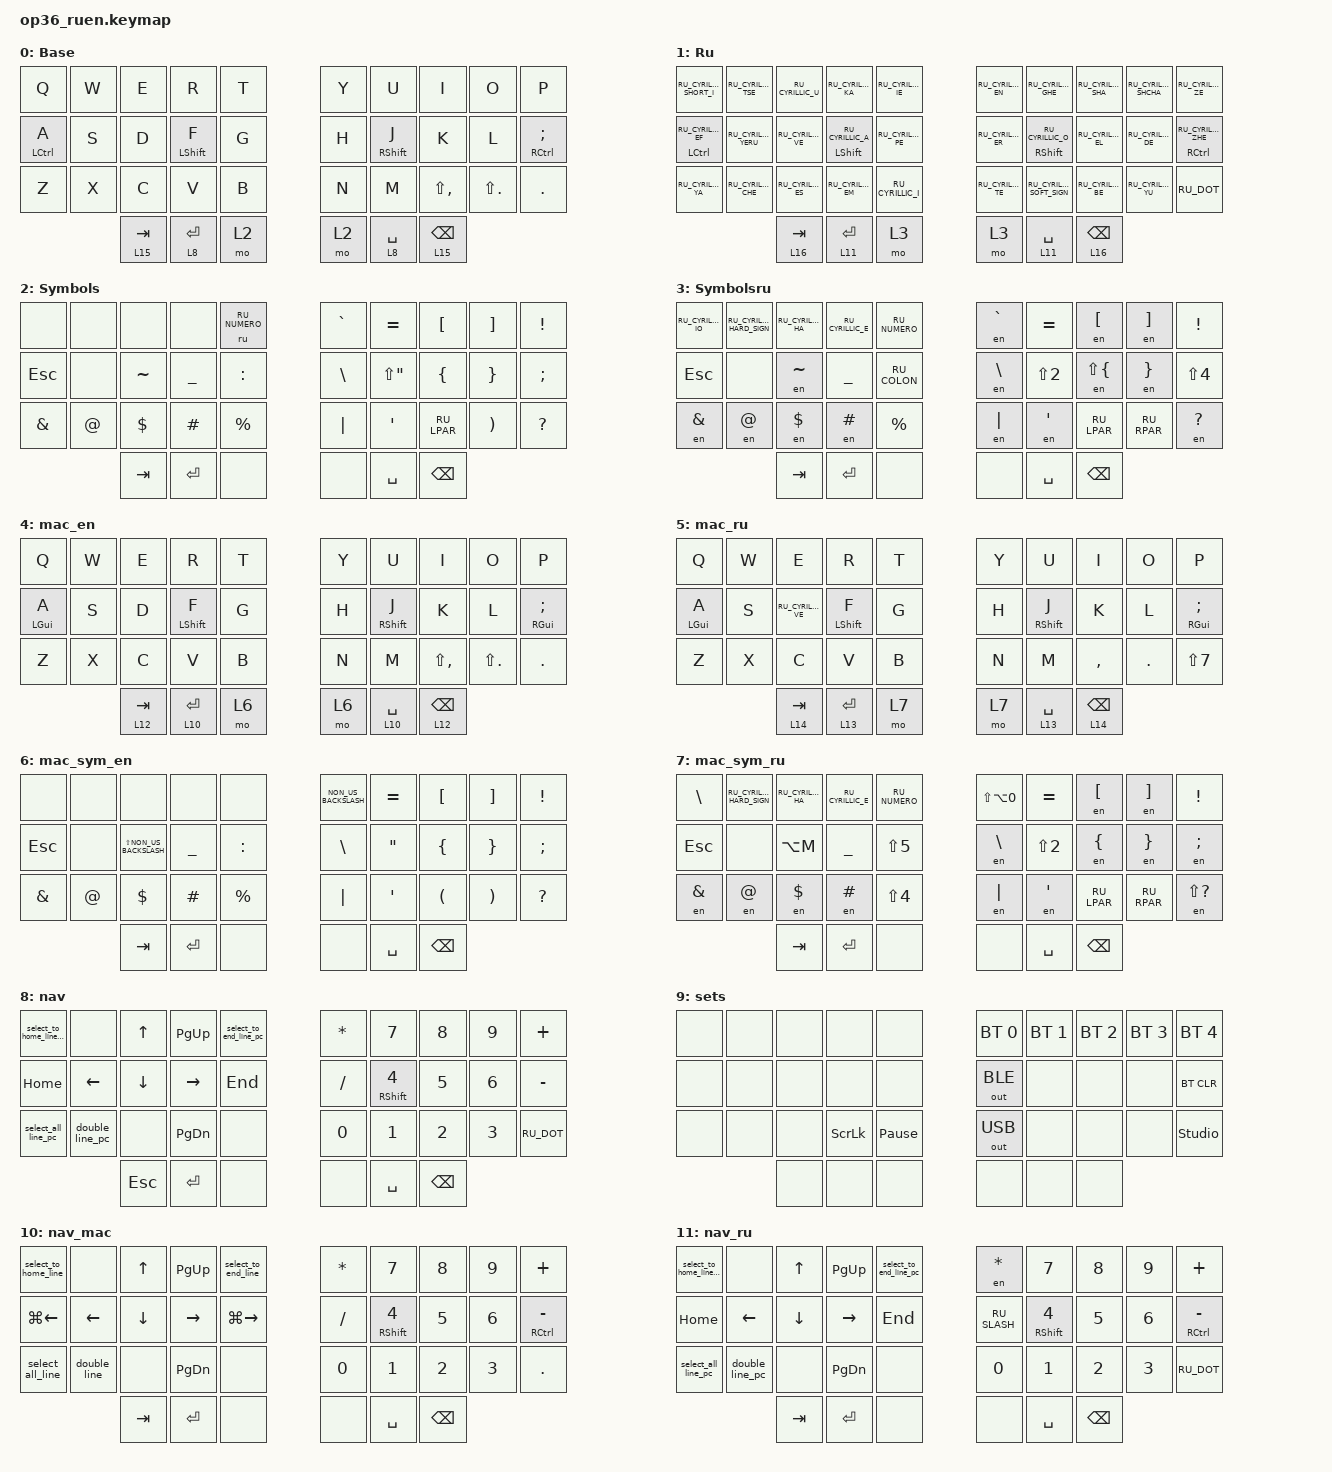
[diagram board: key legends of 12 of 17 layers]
#include "keys_ru.h"
#include "keys_ru.h"
#include <behaviors.dtsi>
#include <dt-bindings/zmk/bt.h>
#include <dt-bindings/zmk/keys.h>
#include <dt-bindings/zmk/outputs.h>

&mt {
    quick-tap-ms = <200>;
    flavor = "tap-preferred";
    require-prior-idle-ms = <125>;
};

/ {
    behaviors {
        hml: home_row_mod_left {
            compatible = "zmk,behavior-hold-tap";
            #binding-cells = <2>;
            flavor = "balanced";
            require-prior-idle-ms = <100>;
            tapping-term-ms = <160>;
            quick-tap-ms = <120>;
            bindings = <&kp>, <&kp>;

            hold-trigger-key-positions = <5 6 7 8 9 15 16 17 18 19 25 26 27 28 29 33 34 35>;
            hold-trigger-on-release;
        };

        hmr: home_row_mod_right {
            compatible = "zmk,behavior-hold-tap";
            #binding-cells = <2>;
            flavor = "balanced";
            require-prior-idle-ms = <100>;
            tapping-term-ms = <160>;
            quick-tap-ms = <120>;
            bindings = <&kp>, <&kp>;

            hold-trigger-key-positions = <0 1 2 3 4 10 11 12 13 14 20 21 22 23 24 30 31 32>;
            hold-trigger-on-release;
        };
    };

    combos {
        compatible = "zmk,combos";

        cmben {
            bindings = <&layer_en>;
            key-positions = <12 13>;
            layers = <1>;
        };

        cmbru {
            bindings = <&layer_ru>;
            key-positions = <12 13>;
            layers = <0>;
        };

        to_mac {
            bindings = <&mac_layer_en>;
            key-positions = <31 34>;
            layers = <0 1>;
        };

        to_base {
            bindings = <&layer_en>;
            key-positions = <30 35>;
            layers = <4 5>;
        };

        cmd_mac_ru {
            bindings = <&mac_layer_ru>;
            key-positions = <12 13>;
            layers = <4>;
        };

        cmd_mac_en {
            bindings = <&mac_layer_en>;
            key-positions = <12 13>;
            layers = <5>;
        };

        colon_en {
            bindings = <&kp COLON>;
            key-positions = <16 17>;
            layers = <0 2 4 6>;
        };

        colon_ru {
            bindings = <&kp RU_COLON>;
            key-positions = <16 17>;
            layers = <1 3>;
        };

        comma_en {
            bindings = <&kp COMMA>;
            key-positions = <26 27>;
            layers = <0 2 4 6 8>;
        };

        comma_ru {
            bindings = <&kp LS(SLASH)>;
            key-positions = <26 27>;
            layers = <1 3 11>;
        };

        to_layer_en {
            bindings = <&to 0>;
            key-positions = <0 3>;
            layers = <1>;
        };

        to_layer_mac_en {
            bindings = <&to 4>;
            key-positions = <0 3>;
            layers = <5>;
        };

        comma_mac_ru {
            bindings = <&kp LS(NUMBER_6)>;
            key-positions = <26 27>;
            layers = <5 7>;
        };

        colon_mac_ru {
            bindings = <&kp LS(NUMBER_5)>;
            key-positions = <16 17>;
            layers = <5 7>;
        };

        layer_en {
            bindings = <&kp NUMBER_0>;
            key-positions = <32 33>;
            layers = <0>;
        };

        layer_ru {
            bindings = <&kp NUMBER_1>;
            key-positions = <32 33>;
            layers = <1>;
        };

        layer_mac {
            bindings = <&kp NUMBER_4>;
            key-positions = <32 33>;
            layers = <4>;
        };

        layer_mac_ru {
            bindings = <&kp NUMBER_5>;
            key-positions = <32 33>;
            layers = <5>;
        };

        alt_l {
            bindings = <&kp LEFT_ALT>;
            key-positions = <11 12>;
        };

        alt_r {
            bindings = <&kp RIGHT_ALT>;
            key-positions = <17 18>;
        };

        dont_tap_to_mac {
            bindings = <&none>;
            key-positions = <31 34>;
            layers = <4 5>;
        };

        dont_tap_to_base {
            bindings = <&none>;
            key-positions = <30 35>;
            layers = <0 1>;
        };

        mac_ctrl_left {
            bindings = <&kp LCTRL>;
            key-positions = <21 22>;
            layers = <4 5 6 7 10 13 12>;
        };

        mac_ctrl_right {
            bindings = <&kp RCTRL>;
            key-positions = <27 28>;
            layers = <4 5 6 7 10 13 12>;
        };

        layer_sets {
            bindings = <&mo 9>;
            key-positions = <2 3>;
        };

        pc_gui_left {
            bindings = <&kp LEFT_GUI>;
            key-positions = <22 21>;
            layers = <0 1 2 3 8 9 11 15 16>;
        };

        pc_gui_right {
            bindings = <&kp LEFT_GUI>;
            key-positions = <27 28>;
            layers = <0 1 2 3 8 9 11 15 16>;
        };
    };

    macros {
        to_ru: to_ru {
            compatible = "zmk,behavior-macro";
            #binding-cells = <0>;
            bindings = <&kp LC(LS(NUMBER_2))>;
            label = "TO_RU";
            wait-ms = <0>;
            tap-ms = <30>;
        };

        to_en: to_en {
            compatible = "zmk,behavior-macro";
            #binding-cells = <0>;
            bindings = <&kp LS(LC(NUMBER_1))>;
            label = "TO_EN";
            wait-ms = <0>;
            tap-ms = <30>;
        };

        layer_en: layer_en {
            compatible = "zmk,behavior-macro";
            #binding-cells = <0>;
            bindings = <&to 0 &to_en>;
            label = "LAYER_EN";
            wait-ms = <0>;
            tap-ms = <30>;
        };

        layer_ru: layer_ru {
            compatible = "zmk,behavior-macro";
            #binding-cells = <0>;
            bindings = <&to 1 &to_ru>;
            label = "LAYER_RU";
            tap-ms = <30>;
            wait-ms = <0>;
        };

        en: en {
            compatible = "zmk,behavior-macro-one-param";
            #binding-cells = <1>;
            bindings =
                <&to_en>,
                <&macro_wait_time 50>,
                <&macro_press>,
                <&macro_param_1to1 &kp MACRO_PLACEHOLDER>,
                <&macro_pause_for_release>,
                <&macro_release>,
                <&macro_param_1to1 &kp MACRO_PLACEHOLDER>,
                <&macro_tap>,
                <&macro_wait_time 50>,
                <&to_ru>;

            label = "EN";
            wait-ms = <30>;
            tap-ms = <30>;
        };

        mac_layer_ru: mac_layer_ru {
            compatible = "zmk,behavior-macro";
            #binding-cells = <0>;
            bindings = <&to 5 &to_ru>;
            label = "MAC_LAYER_RU";
        };

        mac_layer_en: mac_layer_en {
            compatible = "zmk,behavior-macro";
            #binding-cells = <0>;
            bindings = <&to 4 &to_en>;
            label = "MAC_LAYER_EN";
        };

        select_all_line: to_all_line {
            compatible = "zmk,behavior-macro";
            #binding-cells = <0>;
            bindings =
                <&kp LG(LEFT)>,
                <&macro_wait_time 30>,
                <&kp LS(LG(RIGHT))>;

            label = "TO_ALL_LINE";
        };

        code_block: code_block {
            compatible = "zmk,behavior-macro";
            #binding-cells = <0>;
            bindings =
                <&kp GRAVE &kp GRAVE &kp GRAVE &kp R &kp U &kp S &kp T>,
                <&macro_wait_time 50>,
                <&kp ENTER>,
                <&macro_wait_time 50>,
                <&kp GRAVE &kp GRAVE &kp GRAVE>,
                <&macro_wait_time 50>,
                <&kp UP>;

            label = "CODE_BLOCK";
        };

        ru: ru {
            compatible = "zmk,behavior-macro-one-param";
            #binding-cells = <1>;
            bindings =
                <&to_ru>,
                <&macro_wait_time 50>,
                <&macro_press>,
                <&macro_param_1to1 &kp MACRO_PLACEHOLDER>,
                <&macro_pause_for_release>,
                <&macro_release>,
                <&macro_param_1to1 &kp MACRO_PLACEHOLDER>,
                <&macro_tap>,
                <&macro_wait_time 50>,
                <&to_en>;

            label = "RU";
            wait-ms = <30>;
            tap-ms = <30>;
        };

        double_line: double_line {
            compatible = "zmk,behavior-macro";
            #binding-cells = <0>;
            bindings =
                <&kp LG(LEFT)>,
                <&macro_wait_time 20>,
                <&kp LS(LG(RIGHT))>,
                <&macro_wait_time 20>,
                <&kp LG(C)>,
                <&macro_wait_time 20>,
                <&kp LG(RIGHT)>,
                <&macro_wait_time 20>,
                <&kp ENTER>,
                <&macro_wait_time 20>,
                <&kp LG(V)>;

            label = "DOUBLE_LINE";
        };

        select_to_home_line: select_to_home_line {
            compatible = "zmk,behavior-macro";
            #binding-cells = <0>;
            bindings = <&kp LS(LG(LEFT))>;
            label = "SELECT_TO_HOME_LINE";
        };

        select_to_end_line: select_to_end_line {
            compatible = "zmk,behavior-macro";
            #binding-cells = <0>;
            bindings = <&kp LS(LG(RIGHT))>;
            label = "SELECT_TO_END_LINE";
        };

        select_all_line_pc: select_all_line_pc {
            compatible = "zmk,behavior-macro";
            #binding-cells = <0>;
            bindings = <&kp HOME>, <&macro_wait_time 30>, <&kp LS(END)>;

            label = "SELECT_ALL_LINE_PC";
        };

        select_to_home_line_pc: to_home_line_pc {
            compatible = "zmk,behavior-macro";
            #binding-cells = <0>;
            bindings = <&kp LS(HOME)>;
            label = "TO_HOME_LINE_PC";
        };

        select_to_end_line_pc: to_end_line_pc {
            compatible = "zmk,behavior-macro";
            #binding-cells = <0>;
            bindings = <&kp LS(END)>;
            label = "TO_END_LINE_PC";
        };

        double_line_pc: double_line_pc {
            compatible = "zmk,behavior-macro";
            #binding-cells = <0>;
            bindings =
                <&kp HOME>,
                <&macro_wait_time 20>,
                <&kp LS(END)>,
                <&macro_wait_time 20>,
                <&kp LC(C)>,
                <&macro_wait_time 20>,
                <&kp END>,
                <&macro_wait_time 20>,
                <&kp ENTER>,
                <&macro_wait_time 20>,
                <&kp LC(V)>;

            label = "DOUBLE_LINE_PC";
        };
    };

    keymap {
        compatible = "zmk,keymap";

        en {
            bindings = <
  &kp Q         &kp W  &kp E  &kp R              &kp T                        &kp Y        &kp U             &kp I          &kp O        &kp P
  &hml LCTRL A  &kp S  &kp D  &hml LEFT_SHIFT F  &kp G                        &kp H        &hmr RSHIFT J     &kp K          &kp L        &hmr RCTRL SEMICOLON
  &kp Z         &kp X  &kp C  &kp V              &kp B                        &kp N        &kp M             &kp LS(COMMA)  &kp LS(DOT)  &kp DOT
                              &lt 15 TAB         &lt 8 ENTER  &mo 2    &mo 2  &lt 8 SPACE  &lt 15 BACKSPACE
            >;

            display-name = "Base";
        };

        ru {
            bindings = <
  &kp RU_CYRILLIC_SHORT_I    &kp RU_CYRILLIC_TSE   &kp RU_CYRILLIC_U   &kp RU_CYRILLIC_KA         &kp RU_CYRILLIC_IE                  &kp RU_CYRILLIC_EN  &kp RU_CYRILLIC_GHE             &kp RU_CYRILLIC_SHA  &kp RU_CYRILLIC_SHCHA  &kp RU_CYRILLIC_ZE
  &hml LCTRL RU_CYRILLIC_EF  &kp RU_CYRILLIC_YERU  &kp RU_CYRILLIC_VE  &hml LSHIFT RU_CYRILLIC_A  &kp RU_CYRILLIC_PE                  &kp RU_CYRILLIC_ER  &hmr RIGHT_SHIFT RU_CYRILLIC_O  &kp RU_CYRILLIC_EL   &kp RU_CYRILLIC_DE     &hmr RCTRL RU_CYRILLIC_ZHE
  &kp RU_CYRILLIC_YA         &kp RU_CYRILLIC_CHE   &kp RU_CYRILLIC_ES  &kp RU_CYRILLIC_EM         &kp RU_CYRILLIC_I                   &kp RU_CYRILLIC_TE  &kp RU_CYRILLIC_SOFT_SIGN       &kp RU_CYRILLIC_BE   &kp RU_CYRILLIC_YU     &kp RU_DOT
                                                                       &lt 16 TAB                 &lt 11 ENTER        &mo 3    &mo 3  &lt 11 SPACE        &lt 16 BACKSPACE
            >;

            display-name = "Ru";
        };

        sym_en {
            bindings = <
  &none          &none        &none       &none           &ru RU_NUMERO                  &kp GRAVE      &kp EQUAL              &kp LEFT_BRACKET  &kp RIGHT_BRACKET      &kp EXCL
  &kp ESCAPE     &none        &kp TILDE   &kp UNDERSCORE  &kp COLON                      &kp BACKSLASH  &kp LS(DOUBLE_QUOTES)  &kp LEFT_BRACE    &kp RIGHT_BRACE        &kp SEMICOLON
  &kp AMPERSAND  &kp AT_SIGN  &kp DOLLAR  &kp HASH        &kp PERCENT                    &kp PIPE       &kp SINGLE_QUOTE       &kp RU_LPAR       &kp RIGHT_PARENTHESIS  &kp QUESTION
                                          &kp TAB         &kp ENTER      &none    &none  &kp SPACE      &kp BACKSPACE
            >;

            display-name = "Symbols";
        };

        sym_ru {
            bindings = <
  &kp RU_CYRILLIC_IO  &kp RU_CYRILLIC_HARD_SIGN  &kp RU_CYRILLIC_HA  &kp RU_CYRILLIC_E  &kp RU_NUMERO                  &en GRAVE      &kp EQUAL         &en LEFT_BRACKET    &en RIGHT_BRACKET  &kp EXCL
  &kp ESC             &none                      &en TILDE           &kp UNDERSCORE     &kp RU_COLON                   &en BACKSLASH  &kp LS(NUMBER_2)  &en LS(LEFT_BRACE)  &en RIGHT_BRACE    &kp LS(NUMBER_4)
  &en AMPERSAND       &en AT_SIGN                &en DOLLAR          &en HASH           &kp PERCENT                    &en PIPE       &en SINGLE_QUOTE  &kp RU_LPAR         &kp RU_RPAR        &en QUESTION
                                                                     &kp TAB            &kp ENTER      &none    &none  &kp SPACE      &kp BACKSPACE
            >;

            display-name = "Symbolsru";
        };

        mac_en {
            bindings = <
  &kp Q            &kp W  &kp E  &kp R              &kp T                         &kp Y         &kp U               &kp I          &kp O        &kp P
  &hml LEFT_GUI A  &kp S  &kp D  &hml LEFT_SHIFT F  &kp G                         &kp H         &hmr RIGHT_SHIFT J  &kp K          &kp L        &hmr RIGHT_GUI SEMI
  &kp Z            &kp X  &kp C  &kp V              &kp B                         &kp N         &kp M               &kp LS(COMMA)  &kp LS(DOT)  &kp DOT
                                 &lt 12 TAB         &lt 10 ENTER  &mo 6    &mo 6  &lt 10 SPACE  &lt 12 BACKSPACE
            >;
        };

        mac_ru {
            bindings = <
  &kp Q            &kp W  &kp E               &kp R              &kp T                         &kp Y         &kp U               &kp I      &kp O    &kp P
  &hml LEFT_GUI A  &kp S  &kp RU_CYRILLIC_VE  &hml LEFT_SHIFT F  &kp G                         &kp H         &hmr RIGHT_SHIFT J  &kp K      &kp L    &hmr RIGHT_GUI SEMI
  &kp Z            &kp X  &kp C               &kp V              &kp B                         &kp N         &kp M               &kp COMMA  &kp DOT  &kp LS(NUMBER_7)
                                              &lt 14 TAB         &lt 13 ENTER  &mo 7    &mo 7  &lt 13 SPACE  &lt 14 BACKSPACE
            >;
        };

        mac_sym_en {
            bindings = <
  &none          &none        &none                     &none           &none                        &kp NON_US_BACKSLASH  &kp EQUAL         &kp LEFT_BRACKET      &kp RIGHT_BRACKET      &kp EXCL
  &kp ESCAPE     &none        &kp LS(NON_US_BACKSLASH)  &kp UNDERSCORE  &kp COLON                    &kp BACKSLASH         &kp DQT           &kp LEFT_BRACE        &kp RIGHT_BRACE        &kp SEMICOLON
  &kp AMPERSAND  &kp AT_SIGN  &kp DOLLAR                &kp HASH        &kp PERCENT                  &kp PIPE              &kp SINGLE_QUOTE  &kp LEFT_PARENTHESIS  &kp RIGHT_PARENTHESIS  &kp QUESTION
                                                        &kp TAB         &kp ENTER    &none    &none  &kp SPACE             &kp BACKSPACE
            >;
        };

        mac_sym_ru {
            bindings = <
  &kp BACKSLASH  &kp RU_CYRILLIC_HARD_SIGN  &kp RU_CYRILLIC_HA  &kp RU_CYRILLIC_E  &kp RU_NUMERO                     &kp LS(LA(NUMBER_0))  &kp EQUAL         &en LEFT_BRACKET  &en RIGHT_BRACKET  &kp EXCL
  &kp ESCAPE     &none                      &kp LA(M)           &kp UNDERSCORE     &kp LS(NUMBER_5)                  &en BACKSLASH         &kp LS(NUMBER_2)  &en LEFT_BRACE    &en RIGHT_BRACE    &en SEMICOLON
  &en AMPERSAND  &en AT_SIGN                &en DOLLAR          &en HASH           &kp LS(NUMBER_4)                  &en PIPE              &en SINGLE_QUOTE  &kp RU_LPAR       &kp RU_RPAR        &en LS(QUESTION)
                                                                &kp TAB            &kp ENTER         &none    &none  &kp SPACE             &kp BACKSPACE
            >;
        };

        nav {
            bindings = <
  &select_to_home_line_pc  &none            &kp UP    &kp PAGE_UP    &select_to_end_line_pc                  &kp ASTERISK  &kp N7                     &kp N8        &kp N9        &kp PLUS
  &kp HOME                 &kp LEFT         &kp DOWN  &kp RIGHT      &kp END                                 &kp SLASH     &hmr RIGHT_SHIFT NUMBER_4  &kp NUMBER_5  &kp NUMBER_6  &kp MINUS
  &select_all_line_pc      &double_line_pc  &none     &kp PAGE_DOWN  &none                                   &kp N0        &kp N1                     &kp N2        &kp N3        &kp RU_DOT
                                                      &kp ESC        &kp ENTER               &none    &none  &kp SPACE     &kp BACKSPACE
            >;
        };

        sets {
            bindings = <
  &none  &none  &none  &none           &none                            &bt BT_SEL 0  &bt BT_SEL 1  &bt BT_SEL 2  &bt BT_SEL 3  &bt BT_SEL 4
  &none  &none  &none  &none           &none                            &out OUT_BLE  &none         &none         &none         &bt BT_CLR
  &none  &none  &none  &kp SCROLLLOCK  &kp PAUSE_BREAK                  &out OUT_USB  &none         &none         &none         &studio_unlock
                       &none           &none            &none    &none  &none         &none
            >;
        };

        nav_mac {
            bindings = <
  &select_to_home_line  &none         &kp UP    &kp PAGE_UP    &select_to_end_line                  &kp STAR   &kp N7                     &kp N8        &kp N9        &kp PLUS
  &kp LG(LEFT)          &kp LEFT      &kp DOWN  &kp RIGHT      &kp LG(RIGHT)                        &kp SLASH  &hmr RIGHT_SHIFT NUMBER_4  &kp NUMBER_5  &kp NUMBER_6  &hmr RCTRL MINUS
  &select_all_line      &double_line  &none     &kp PAGE_DOWN  &none                                &kp N0     &kp N1                     &kp N2        &kp N3        &kp DOT
                                                &kp TAB        &kp ENTER            &none    &none  &kp SPACE  &kp BACKSPACE
            >;
        };

        nav_ru {
            bindings = <
  &select_to_home_line_pc  &none            &kp UP    &kp PAGE_UP    &select_to_end_line_pc                  &en ASTERISK  &kp N7                     &kp N8        &kp N9        &kp PLUS
  &kp HOME                 &kp LEFT         &kp DOWN  &kp RIGHT      &kp END                                 &kp RU_SLASH  &hmr RIGHT_SHIFT NUMBER_4  &kp NUMBER_5  &kp NUMBER_6  &hmr RCTRL MINUS
  &select_all_line_pc      &double_line_pc  &none     &kp PAGE_DOWN  &none                                   &kp N0        &kp N1                     &kp N2        &kp N3        &kp RU_DOT
                                                      &kp TAB        &kp ENTER               &none    &none  &kp SPACE     &kp BACKSPACE
            >;
        };

        lavel_3_mac_en {
            bindings = <
  &kp F1        &kp F2  &kp F3     &kp F4      &kp F5                     &kp F8     &kp F9         &kp F10        &kp F11           &kp F12
  &kp CAPSLOCK  &none   &kp SPACE  &kp DELETE  &kp F6                     &kp F7     &none          &kp CARET      &none             &none
  &none         &none   &none      &none       &none                      &none      &none          &kp LESS_THAN  &kp GREATER_THAN  &none
                                   &kp TAB     &kp ENTER  &none    &none  &kp SPACE  &kp BACKSPACE
            >;
        };

        nav_mac_ru {
            bindings = <
  &select_to_home_line  &none         &kp UP    &kp PAGE_UP    &select_to_end_line                  &en STAR   &kp N7                     &kp N8        &kp N9        &kp PLUS
  &kp LG(LEFT)          &kp LEFT      &kp DOWN  &kp RIGHT      &kp LG(RIGHT)                        &kp SLASH  &hmr RIGHT_SHIFT NUMBER_4  &kp NUMBER_5  &kp NUMBER_6  &hmr RCTRL MINUS
  &select_all_line      &double_line  &none     &kp PAGE_DOWN  &none                                &kp N0     &kp N1                     &kp N2        &kp N3        &kp LS(NUMBER_7)
                                                &kp TAB        &kp ENTER            &none    &none  &kp SPACE  &kp BACKSPACE
            >;
        };

        lavel_3_mac_ru {
            bindings = <
  &kp F1        &kp F2  &kp F3     &kp F4      &kp F5                     &kp F8     &kp F9         &kp F10        &kp F11           &kp F12
  &kp CAPSLOCK  &none   &kp SPACE  &kp DELETE  &kp F6                     &kp F7     &none          &en CARET      &none             &none
  &none         &none   &none      &none       &none                      &none      &none          &en LESS_THAN  &en GREATER_THAN  &none
                                   &kp TAB     &kp ENTER  &none    &none  &kp SPACE  &kp BACKSPACE
            >;
        };

        lavel_3_en {
            bindings = <
  &kp F1        &kp F2  &kp F3     &kp F4      &kp F5                     &kp F8     &kp F9         &kp F10        &kp F11           &kp F12
  &kp CAPSLOCK  &none   &kp SPACE  &kp DELETE  &kp F6                     &kp F7     &none          &kp CARET      &none             &kp C_PLAY_PAUSE
  &none         &none   &none      &none       &none                      &none      &none          &kp LESS_THAN  &kp GREATER_THAN  &none
                                   &kp TAB     &kp ENTER  &none    &none  &kp SPACE  &kp BACKSPACE
            >;
        };

        lavel_3_ru {
            bindings = <
  &kp F1        &kp F2  &kp F3     &kp F4      &kp F5                     &kp F8     &kp F9         &kp F10        &kp F11           &kp F12
  &kp CAPSLOCK  &none   &kp SPACE  &kp DELETE  &kp F6                     &kp F7     &none          &en CARET      &kp C_PLAY        &kp C_PLAY_PAUSE
  &none         &none   &none      &none       &none                      &none      &none          &en LESS_THAN  &en GREATER_THAN  &kp K_PLAY_PAUSE
                                   &kp TAB     &kp ENTER  &none    &none  &kp SPACE  &kp BACKSPACE
            >;
        };
    };
};
